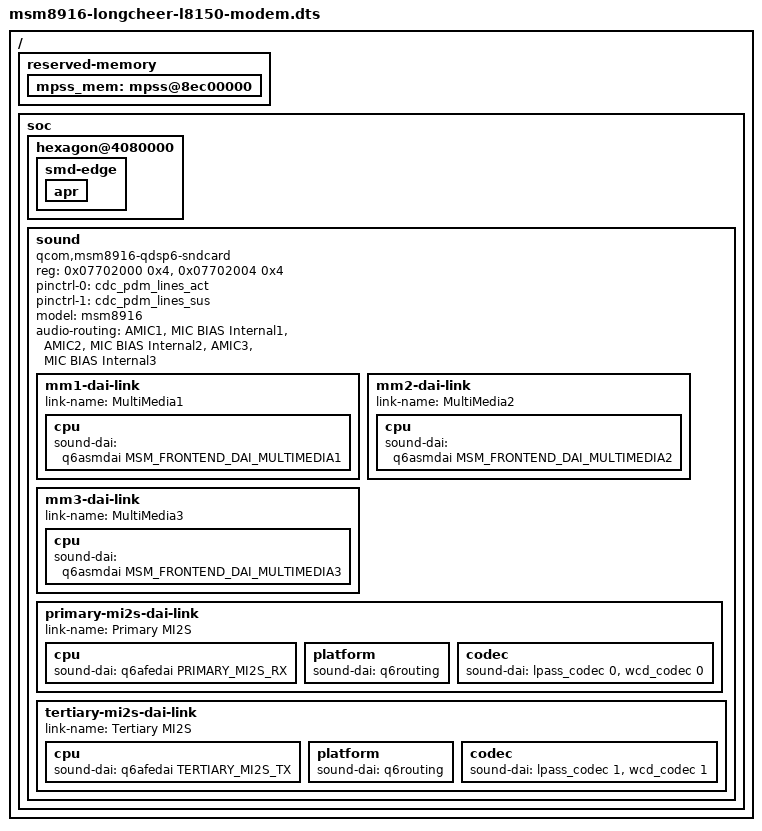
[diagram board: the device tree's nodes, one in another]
// SPDX-License-Identifier: GPL-2.0-only
#include "msm8916-longcheer-l8150.dts"
#include <dt-bindings/sound/qcom,q6afe.h>
#include <dt-bindings/sound/qcom,q6asm.h>

/ {
	reserved-memory {
		mpss_mem: mpss@8ec00000 {
			status = "okay";
		};
	};

	soc {
		/delete-node/ sound;

		hexagon@4080000 {
			status = "okay";

			smd-edge {
				apr {
					status = "okay";
				};
			};
		};

		sound {
			compatible = "qcom,msm8916-qdsp6-sndcard";
			reg = <0x07702000 0x4>, <0x07702004 0x4>;
			reg-names = "mic-iomux", "spkr-iomux";

			pinctrl-names = "default", "sleep";
			pinctrl-0 = <&cdc_pdm_lines_act>;
			pinctrl-1 = <&cdc_pdm_lines_sus>;

			model = "msm8916";
			audio-routing =
				"AMIC1", "MIC BIAS Internal1",
				"AMIC2", "MIC BIAS Internal2",
				"AMIC3", "MIC BIAS Internal3";

			mm1-dai-link {
				link-name = "MultiMedia1";
				cpu {
					sound-dai = <&q6asmdai MSM_FRONTEND_DAI_MULTIMEDIA1>;
				};
			};

			mm2-dai-link {
				link-name = "MultiMedia2";
				cpu {
					sound-dai = <&q6asmdai MSM_FRONTEND_DAI_MULTIMEDIA2>;
				};
			};

			mm3-dai-link {
				link-name = "MultiMedia3";
				cpu {
					sound-dai = <&q6asmdai MSM_FRONTEND_DAI_MULTIMEDIA3>;
				};
			};

			primary-mi2s-dai-link {
				link-name = "Primary MI2S";
				cpu {
					sound-dai = <&q6afedai PRIMARY_MI2S_RX>;
				};

				platform {
					sound-dai = <&q6routing>;
				};

				codec {
					sound-dai = <&lpass_codec 0>, <&wcd_codec 0>;
				};
			};

			tertiary-mi2s-dai-link {
				link-name = "Tertiary MI2S";
				cpu {
					sound-dai = <&q6afedai TERTIARY_MI2S_TX>;
				};

				platform {
					sound-dai = <&q6routing>;
				};

				codec {
					sound-dai = <&lpass_codec 1>, <&wcd_codec 1>;
				};
			};
		};
	};
};
